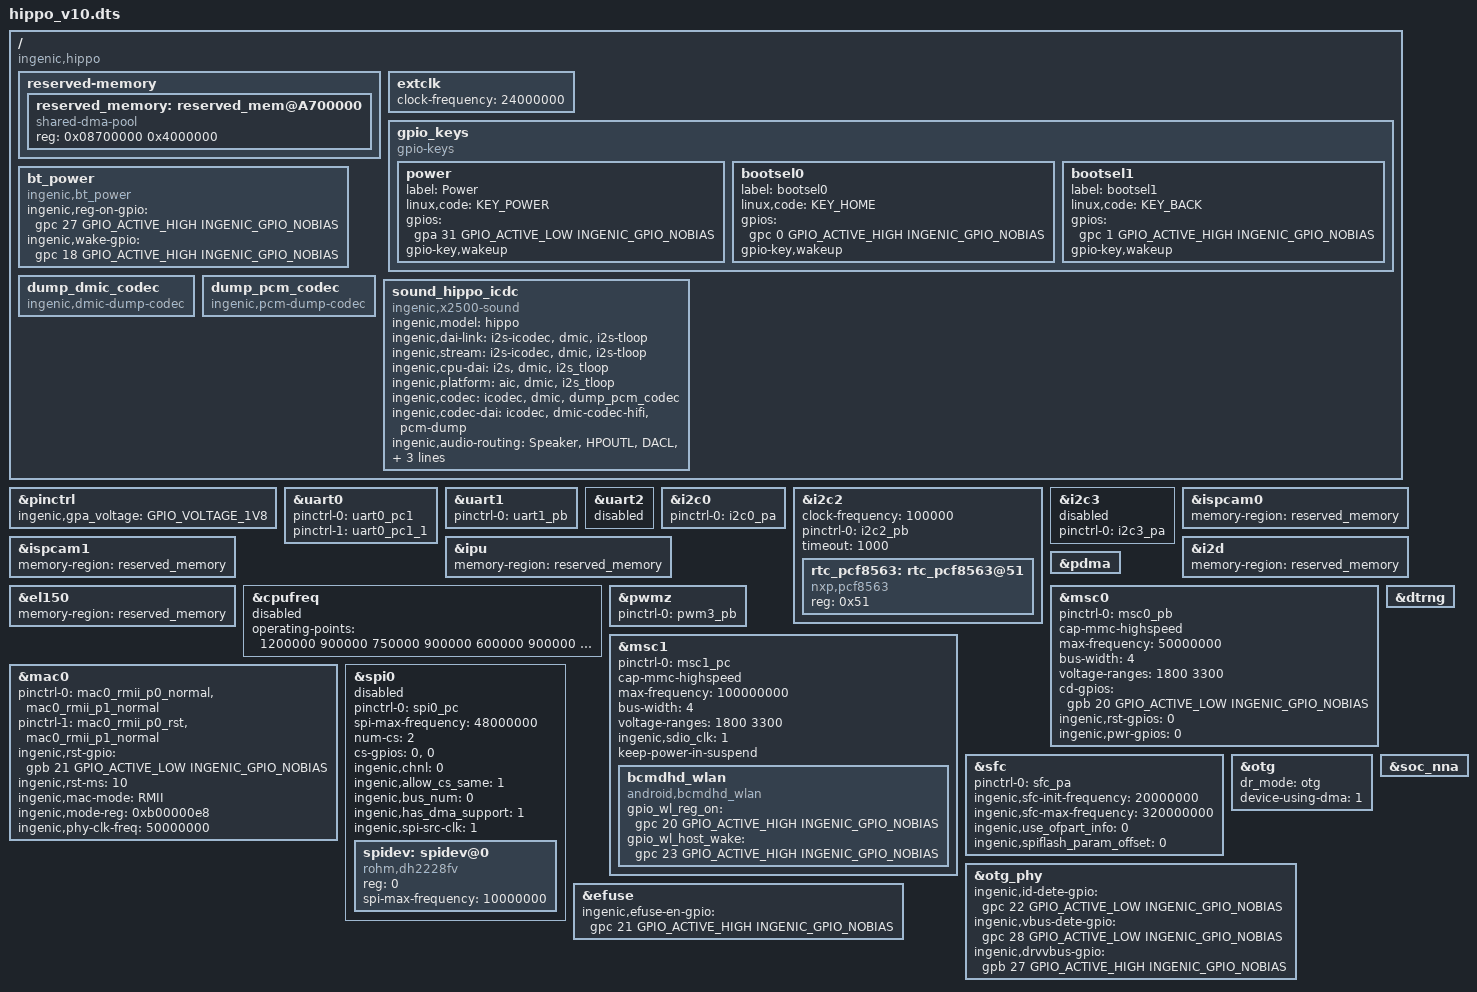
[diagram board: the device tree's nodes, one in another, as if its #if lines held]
/dts-v1/;

#include <dt-bindings/input/input.h>
#include "x2500.dtsi"
#include <dt-bindings/interrupt-controller/irq.h>
#include <generated/autoconf.h>


#ifdef CONFIG_RD_X2000_HALLEY5_CAMERA_3V2
#include "hippo_cameras/RD_X2000_HALLEY5_CAMERA_3V2.dtsi"
#elif CONFIG_RD_X2000_HALLEY5_CAMERA_4V3
#include "hippo_cameras/RD_X2000_HALLEY5_CAMERA_4V3.dtsi"
#elif CONFIG_RD_X2500_HIPPO_CAMERA_1V0
#include "hippo_cameras/RD_X2500_HIPPO_CAMERA_1V0.dtsi"
#elif CONFIG_RD_X2500_HIPPO_CAMERA_1V1
#include "hippo_cameras/RD_X2500_HIPPO_CAMERA_1V1.dtsi"
#elif CONFIG_RD_X2500_HIPPO_CAMERA_BT1120
#include "hippo_cameras/BT1120.dtsi"
#endif

/ {
	compatible = "ingenic,hippo", "ingenic,x2500";
	reserved-memory {
		#address-cells = <1>;
		#size-cells = <1>;
		ranges =<>;

#if 0
		vdev0vring0: vdev0vring0@12400000{
		    compatible = "shared-dma-pool";
			reg = <0x12400000 0x1000>;
			no-map;
		};

		vdev0vring1: vdev0vring1@12401000{
		    compatible = "shared-dma-pool";
			reg = <0x12401000 0x1000>;
			no-map;
		};

		vdev0buffer: vdev0buffer@0CB02000{
			 compatible = "shared-dma-pool";
			 reg = <0x0CB02000 0x8000>;
		 };

		riscv_mcu_ram: riscv_mcu_ram@0C800000{
			 compatible = "shared-dma-pool";
			 reg = <0x0C800000 0x300000>;
		 };
#endif

		reserved_memory: reserved_mem@A700000{
			 compatible = "shared-dma-pool";
			 reg = <0x08700000 0x4000000>;
		 };
	};
};

&pinctrl {
	ingenic,gpa_voltage = <GPIO_VOLTAGE_1V8>;
};

#if 0
&riscv {
	status = "okay";
	memory-region=<&vdev0buffer &vdev0vring0 &vdev0vring1>;
	load-addr=<0x0C800000>;
};
#endif

&uart0 {
	status = "okay";
	pinctrl-names = "default", "default";
	pinctrl-0 = <&uart0_pc1>;
	pinctrl-1 = <&uart0_pc1_1>;
};

&uart1 {
	status = "okay";
	pinctrl-names = "default";
	pinctrl-0 = <&uart1_pb>;
};

&uart2 {
	status = "disable";
};

&i2c0 {
	pinctrl-0 = <&i2c0_pa>;
	pinctrl-names = "default";
	status = "okay";
};

&i2c2 {
	clock-frequency = <100000>;
	pinctrl-0 = <&i2c2_pb>;
	timeout = <1000>;
	pinctrl-names = "default";
	status = "okay";

	rtc_pcf8563:rtc_pcf8563@51{
		compatible = "nxp,pcf8563";
		reg = <0x51>;
		status = "ok";
	    };
};

&i2c3 {
	pinctrl-0 = <&i2c3_pa>;
	pinctrl-names = "default";
#ifdef CONFIG_RD_X2500_HIPPO_CAMERA_BT1120
	status = "disable";
#else
	status = "okay";
#endif
};

&ispcam0 {
	status = "okay";
	memory-region=<&reserved_memory>;
};

&ispcam1 {
	status = "okay";
	memory-region=<&reserved_memory>;
};

&ipu{
	status = "okay";
	memory-region=<&reserved_memory>;
};

&i2d{
	status = "okay";
	memory-region=<&reserved_memory>;
};

&el150 {
	status = "okay";
	memory-region=<&reserved_memory>;
};

&cpufreq {
	status = "disable";
	operating-points = <
		/*KHZ uV */
		1200000	900000
		750000	900000
		600000	900000
		500000	900000
		400000	900000
		375000	900000
		300000	900000
		200000	900000
			>;

};

&pwmz {
	status = "okay";
	pinctrl-names = "default";
	pinctrl-0 = <&pwm3_pb>;
};

&pdma {
	status = "okay";
};

&msc0 {
	status = "okay";
	pinctrl-names = "default";
	pinctrl-0 = <&msc0_pb>;
	cap-mmc-highspeed;
	max-frequency = <50000000>;
	bus-width = <4>;
	voltage-ranges = <1800 3300>;
	cd-gpios = <&gpb 20 GPIO_ACTIVE_LOW INGENIC_GPIO_NOBIAS>;
	/* special property */
	ingenic,rst-gpios = <0>;
	ingenic,pwr-gpios = <0>;
};

&msc1 {
	status = "okay";
	pinctrl-names = "default";
	pinctrl-0 = <&msc1_pc>;
	cap-mmc-highspeed;
	max-frequency = <100000000>;
	bus-width = <4>;
	voltage-ranges = <1800 3300>;

	ingenic,sdio_clk = <1>;
	keep-power-in-suspend;

	bcmdhd_wlan: bcmdhd_wlan {
		 compatible = "android,bcmdhd_wlan";
		 gpio_wl_reg_on = <&gpc 20 GPIO_ACTIVE_HIGH INGENIC_GPIO_NOBIAS>;
		 gpio_wl_host_wake = <&gpc 23 GPIO_ACTIVE_HIGH INGENIC_GPIO_NOBIAS>;
	};
};

&mac0 {
	pinctrl-names = "default", "reset";
	pinctrl-0 = <&mac0_rmii_p0_normal>, <&mac0_rmii_p1_normal>;
	pinctrl-1 = <&mac0_rmii_p0_rst>, <&mac0_rmii_p1_normal>;
	status = "okay";
	ingenic,rst-gpio = <&gpb 21 GPIO_ACTIVE_LOW INGENIC_GPIO_NOBIAS>;
	ingenic,rst-ms = <10>;
	ingenic,mac-mode = <RMII>;
	ingenic,mode-reg = <0xb00000e8>;
	ingenic,phy-clk-freq = <50000000>;
};

&sfc {
	status = "okay";
	pinctrl-names = "default";
	pinctrl-0 = <&sfc_pa>;
	ingenic,sfc-init-frequency = <20000000>;
	ingenic,sfc-max-frequency = <320000000>;
	ingenic,use_ofpart_info      = /bits/ 8 <0>;
	ingenic,spiflash_param_offset = <0>;
};

&spi0 {
	status = "disable";
	pinctrl-names = "default";
	pinctrl-0 = <&spi0_pc>;

	spi-max-frequency = <48000000>;
	num-cs = <2>;
	cs-gpios = <0>, <0>;
	ingenic,chnl = <0>;
	ingenic,allow_cs_same = <1>;
	ingenic,bus_num = <0>;
	ingenic,has_dma_support = <1>;
	ingenic,spi-src-clk = <1>;/*0.ext; 1.ssi*/

	/* Add SPI interface device */
	spidev: spidev@0 {
		compatible = "rohm,dh2228fv";
		reg = <0>;
		spi-max-frequency = <10000000>;
	};
};

&dtrng {
	status = "okay";
};

&otg {
	dr_mode = "otg";
	device-using-dma = <1>;
	status = "okay";
};

&otg_phy {
	status = "okay";
	ingenic,id-dete-gpio = <&gpc 22 GPIO_ACTIVE_LOW INGENIC_GPIO_NOBIAS>;
	ingenic,vbus-dete-gpio = <&gpc 28 GPIO_ACTIVE_LOW INGENIC_GPIO_NOBIAS>;
	ingenic,drvvbus-gpio = <&gpb 27 GPIO_ACTIVE_HIGH INGENIC_GPIO_NOBIAS>;
};

&efuse {
	status = "okay";
	ingenic,efuse-en-gpio = <&gpc 21 GPIO_ACTIVE_HIGH INGENIC_GPIO_NOBIAS>;
};


/ {

	extclk: extclk {
		   clock-frequency = <24000000>;
	};

	gpio_keys: gpio_keys {
		   compatible = "gpio-keys";

		   power {
			   label = "Power";
			   linux,code = <KEY_POWER>;
			   gpios = <&gpa 31 GPIO_ACTIVE_LOW INGENIC_GPIO_NOBIAS>;
			   gpio-key,wakeup;
		   };

		   bootsel0 {
			   label = "bootsel0";
			   linux,code = <KEY_HOME>;
			   gpios = <&gpc 0 GPIO_ACTIVE_HIGH INGENIC_GPIO_NOBIAS>;
			   gpio-key,wakeup;
		   };

		   bootsel1 {
			   label = "bootsel1";
			   linux,code = <KEY_BACK>;
			   gpios = <&gpc 1 GPIO_ACTIVE_HIGH INGENIC_GPIO_NOBIAS>;
			   gpio-key,wakeup;
		   };

	   };

	bt_power {
		compatible = "ingenic,bt_power";
		ingenic,reg-on-gpio = <&gpc 27 GPIO_ACTIVE_HIGH INGENIC_GPIO_NOBIAS>;
		ingenic,wake-gpio = <&gpc 18 GPIO_ACTIVE_HIGH INGENIC_GPIO_NOBIAS>;
	};
};

&soc_nna{
	status="okay";
};

/ {
	dump_dmic_codec:dump_dmic_codec{
		compatible = "ingenic,dmic-dump-codec";
		status = "ok";
	};
	dump_pcm_codec:dump_pcm_codec{
		compatible = "ingenic,pcm-dump-codec";
		status = "ok";
	};

	sound_hippo_icdc {
		status = "ok";
		compatible = "ingenic,x2500-sound";
		ingenic,model = "hippo";
		ingenic,dai-link = "i2s-icodec", "dmic", "i2s-tloop";
		ingenic,stream = "i2s-icodec", "dmic", "i2s-tloop";
		ingenic,cpu-dai = <&i2s>, <&dmic>, <&i2s_tloop>;
		ingenic,platform = <&aic>, <&dmic>, <&i2s_tloop>;
		ingenic,codec = <&icodec>, <&dmic>, <&dump_pcm_codec>;
		ingenic,codec-dai = "icodec", "dmic-codec-hifi", "pcm-dump";
		ingenic,audio-routing = "Speaker", "HPOUTL", "DACL", "MICBIAS" ,
			"ADCL",  "MICL",
			"ADCR",  "MICR";
		ingenic,spken-gpio = <&gpb 22 GPIO_ACTIVE_HIGH INGENIC_GPIO_NOBIAS>;
	};

};

#ifdef CONFIG_STAGE_FW050
#include "hippo_lcd/HIPPO_MIPI_LCD_FW050.dtsi"
#endif

#ifdef CONFIG_STAGE_ZC50289HSHD02
#include "hippo_lcd/HIPPO_MIPI_LCD_ZC50289HSHD02.dtsi"
#endif
